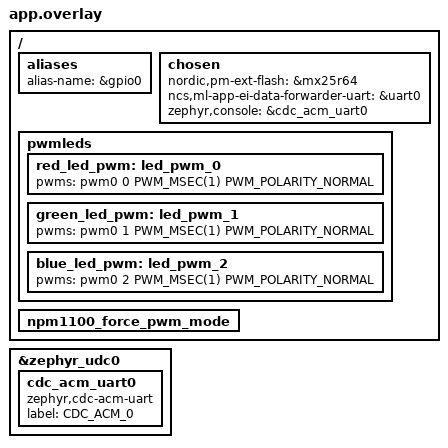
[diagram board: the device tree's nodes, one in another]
/*
 * Copyright (c) 2021 Nordic Semiconductor ASA
 *
 * SPDX-License-Identifier: LicenseRef-Nordic-5-Clause
 */

/ {
	aliases {
		alias-name = &gpio0;
	};
	chosen {
		nordic,pm-ext-flash = &mx25r64;
		ncs,ml-app-ei-data-forwarder-uart = &uart0;
	};
};

/ {
	pwmleds {
		red_led_pwm: led_pwm_0 {
			pwms = <&pwm0 0 PWM_MSEC(1) PWM_POLARITY_NORMAL>;
		};

		green_led_pwm: led_pwm_1 {
			pwms = <&pwm0 1 PWM_MSEC(1) PWM_POLARITY_NORMAL>;
		};

		blue_led_pwm: led_pwm_2 {
			pwms = <&pwm0 2 PWM_MSEC(1) PWM_POLARITY_NORMAL>;
		};
	};
	/*
	leds {
		compatible = "gpio-leds";
		led_3 {
			gpios = <&gpio0 4 GPIO_ACTIVE_LOW>;
		};
		led_4 {
			gpios = <&gpio0 5 GPIO_ACTIVE_HIGH>;
		};
	};
	*/
	/*
	watertap {
		compatible = "nordic";
		wvalve: w_valve {
			gpios = <&gpio0 4 GPIO_ACTIVE_HIGH>;
			label = "GPIO PIN 4";
		};
		msensor: m_sensor {
			gpios = <&gpio0 5 GPIO_ACTIVE_HIGH>;
			label = "GPIO PIN 5";
		};
	};

	aliases {
		wvalvesda = &wvalve;
		msensorscl = &msensor;
	};	
	*/

	npm1100_force_pwm_mode: npm1100_force_pwm_mode {
		status = "okay";
	};

	chosen {
		zephyr,console = &cdc_acm_uart0;
	};
};

&zephyr_udc0 {
	cdc_acm_uart0: cdc_acm_uart0 {
		compatible = "zephyr,cdc-acm-uart";
		label = "CDC_ACM_0";
	};
};
